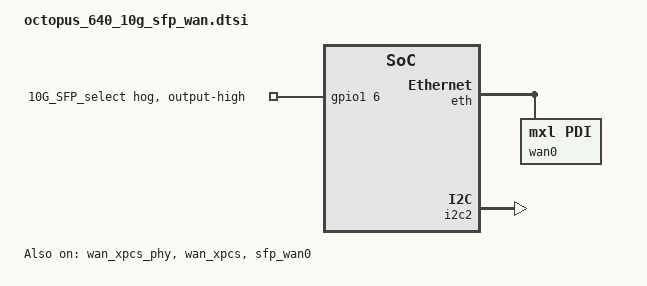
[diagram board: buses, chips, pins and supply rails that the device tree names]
// SPDX-License-Identifier: GPL-2.0
/*
 * Copyright (C) 2024 MaxLinear, Inc.
 */

/* Select 10G PHY WAN */
&gpio1 {
	10GSFP_gpio38 {
		gpio-hog;
		gpios = <6 GPIO_ACTIVE_HIGH>;
		output-high;
		line-name = "10G_SFP_select";
	};
};

/ {
	wan {
		ifname = "eth1";
	};
};

/* WAN XPCS PHY */
&wan_xpcs_phy {
	status = "okay";
};

&wan_xpcs {
	status = "okay";
};

&sfp_wan0 {
	status = "okay";
};

&lpid_config {
	mxl,wan-mode = <LPID_WAN_ETH>;
};

&eth {
	wan0 {
		status = "okay";

		#address-cells = <1>;
		#size-cells = <0>;
		compatible = "mxl,pdi";

		mxl,wan = <1>;
		mxl,dp-dev-port = <2>;
		mxl,dp-port-id = <2>;
		mxl,dp-port-10g;
		mxl,xgmac-id = <2>;
		mxl,pon_hgu_sim = <0>;
		mac = <&gsw_mac0>;
		phy-mode = "10gbase-kr";
		sfp = <&sfp_wan0>;

		wan0_eth: ethernet@8 {
			compatible = "mxl,pdi-port";
			reg = <0>;
			phy-mode = "10gbase-kr";
		};
	};
};

&i2c2 {
	status = "okay";
};
